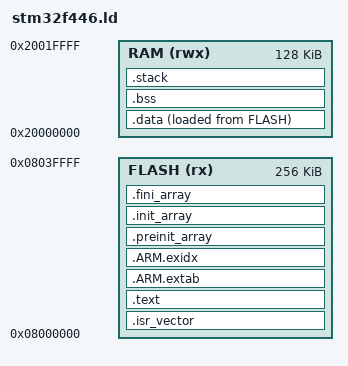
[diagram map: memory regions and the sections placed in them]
/* PROVISIONAL STM32F446RC: 256 KiB flash, 128 KiB SRAM. Verify fitted MCU. */
ENTRY(Reset_Handler)
MEMORY { FLASH (rx) : ORIGIN = 0x08000000, LENGTH = 256K
         RAM (rwx) : ORIGIN = 0x20000000, LENGTH = 128K }
_estack = ORIGIN(RAM) + LENGTH(RAM);
_stack_limit = _estack - 8192;
SECTIONS {
 .isr_vector : { . = ALIGN(4); KEEP(*(.isr_vector)) } >FLASH
 .text : { *(.text*) *(.rodata*) KEEP(*(.init)) KEEP(*(.fini)) . = ALIGN(4); } >FLASH
 .ARM.extab : { *(.ARM.extab*) } >FLASH
 .ARM.exidx : { __exidx_start = .; *(.ARM.exidx*) __exidx_end = .; } >FLASH
 .preinit_array : { PROVIDE_HIDDEN(__preinit_array_start = .); KEEP(*(.preinit_array*)) PROVIDE_HIDDEN(__preinit_array_end = .); } >FLASH
 .init_array : { PROVIDE_HIDDEN(__init_array_start = .); KEEP(*(SORT(.init_array.*))) KEEP(*(.init_array)) PROVIDE_HIDDEN(__init_array_end = .); } >FLASH
 .fini_array : { PROVIDE_HIDDEN(__fini_array_start = .); KEEP(*(.fini_array*)) PROVIDE_HIDDEN(__fini_array_end = .); } >FLASH
 _sidata = LOADADDR(.data);
 .data : { . = ALIGN(4); _sdata = .; *(.data*) . = ALIGN(4); _edata = .; } >RAM AT>FLASH
 .bss (NOLOAD) : { . = ALIGN(8); _sbss = .; *(.bss*) *(COMMON) . = ALIGN(8); _ebss = .; } >RAM
 .stack _stack_limit (NOLOAD) : { . = . + 8192; } >RAM
 /DISCARD/ : { *(.note.GNU-stack) }
}
ASSERT(_ebss <= _stack_limit, "Static RAM overlaps reserved 8 KiB stack")
